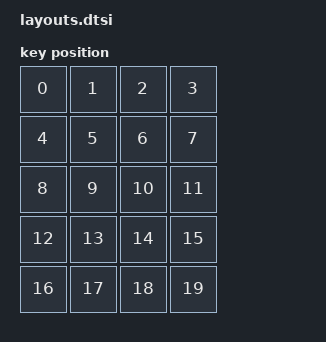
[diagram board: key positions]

#include <physical_layouts.dtsi>
/ {
    physical_layout0: physical_layout0 {
        compatible = "zmk,physical-layout";
        display-name = "Layout";
        keys
            = <&key_physical_attrs 100 100 (-50) 0 0 0 0>
			,<&key_physical_attrs 100 100 50 0 0 0 0>
			,<&key_physical_attrs 100 100 150 0 0 0 0>
			,<&key_physical_attrs 100 100 250 0 0 0 0>
			,<&key_physical_attrs 100 100 (-50) 100 0 0 0>
			,<&key_physical_attrs 100 100 50 100 0 0 0>
			,<&key_physical_attrs 100 100 150 100 0 0 0>
			,<&key_physical_attrs 100 100 250 100 0 0 0>
			,<&key_physical_attrs 100 100 (-50) 200 0 0 0>
			,<&key_physical_attrs 100 100 50 200 0 0 0>
			,<&key_physical_attrs 100 100 150 200 0 0 0>
			,<&key_physical_attrs 100 100 250 200 0 0 0>
			,<&key_physical_attrs 100 100 (-50) 300 0 0 0>
			,<&key_physical_attrs 100 100 50 300 0 0 0>
			,<&key_physical_attrs 100 100 150 300 0 0 0>
			,<&key_physical_attrs 100 100 250 300 0 0 0>
			,<&key_physical_attrs 100 100 (-50) 400 0 0 0>
			,<&key_physical_attrs 100 100 50 400 0 0 0>
			,<&key_physical_attrs 100 100 150 400 0 0 0>
			,<&key_physical_attrs 100 100 250 400 0 0 0>
            ;
    };
};
    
